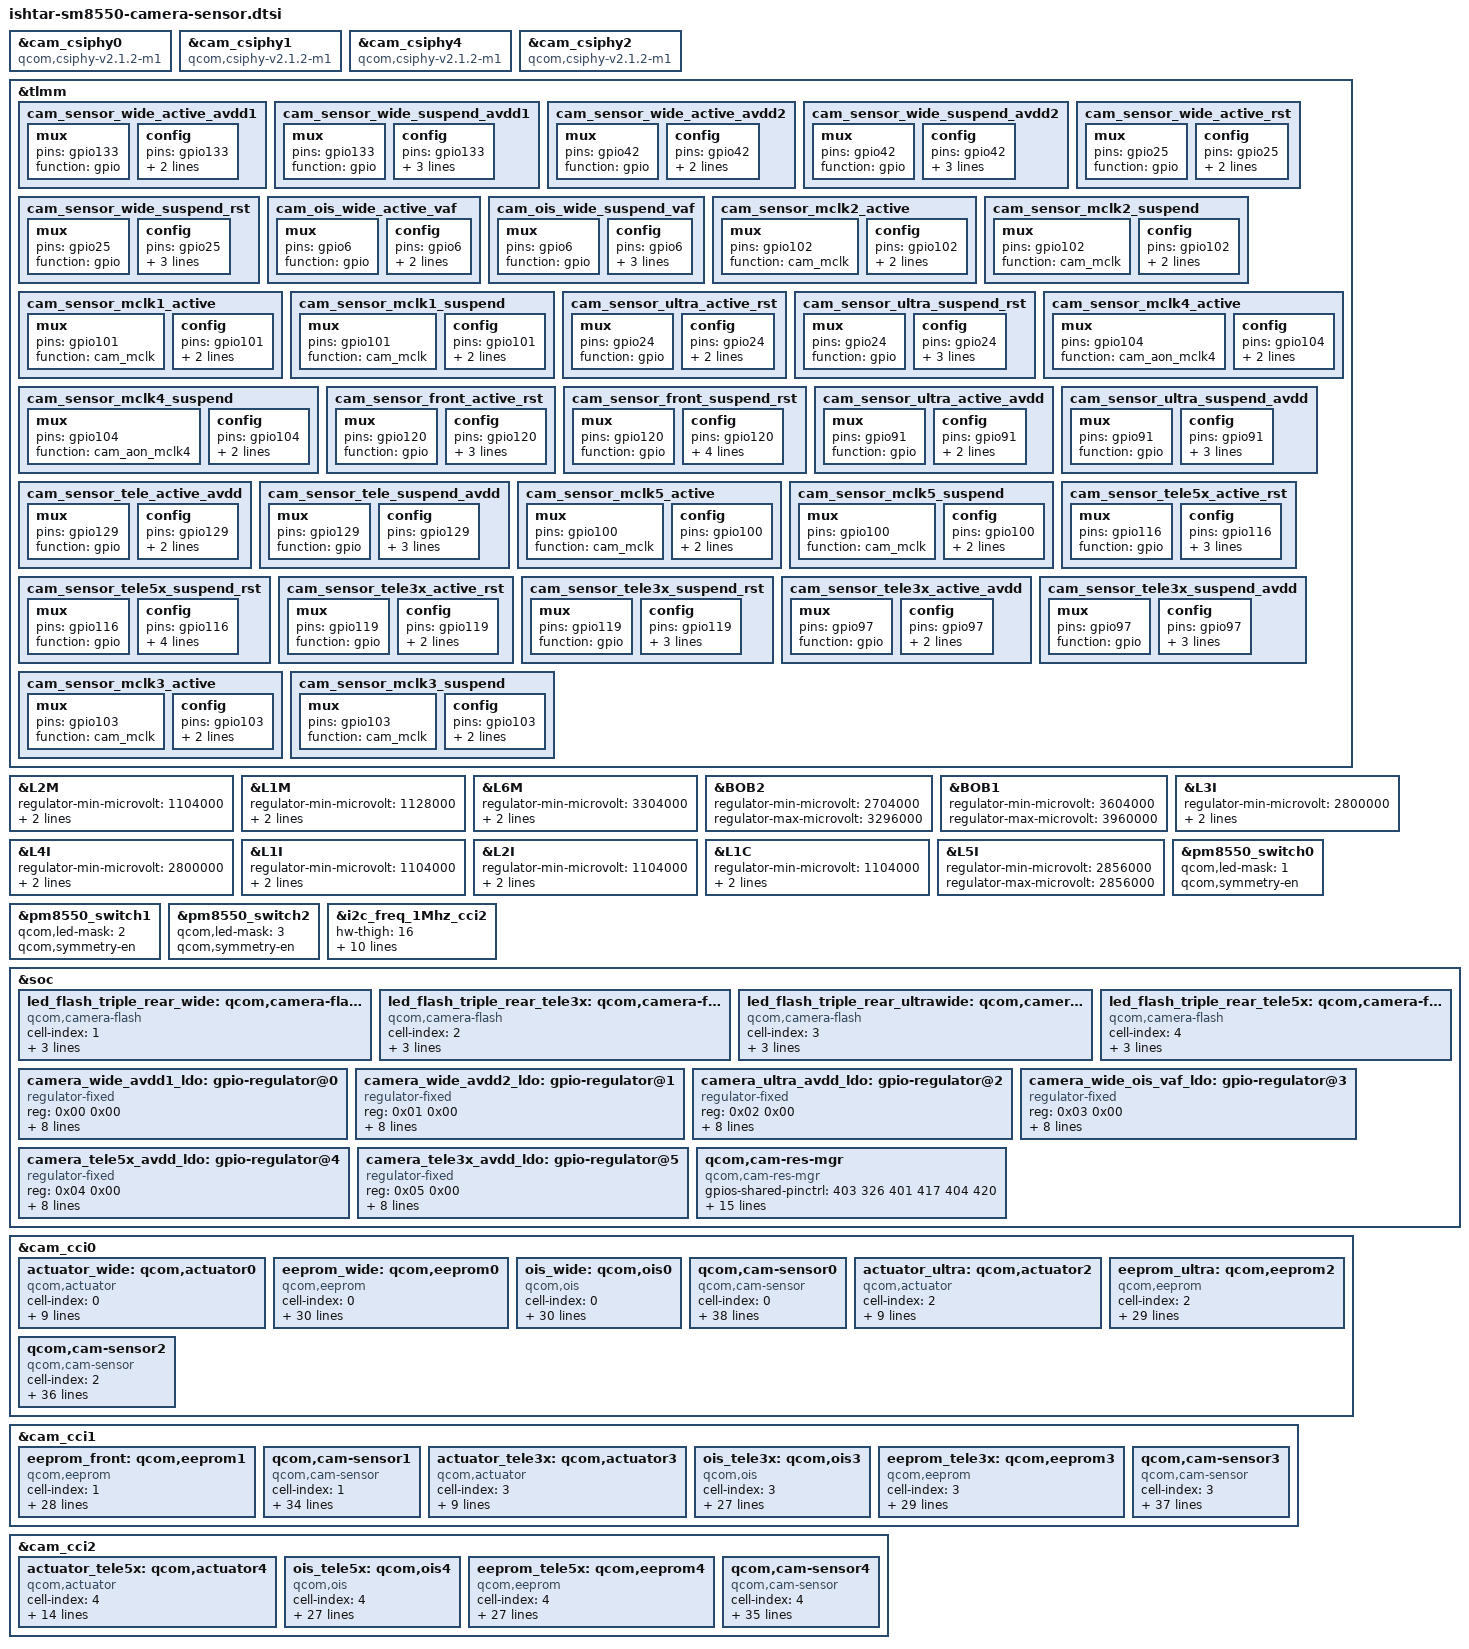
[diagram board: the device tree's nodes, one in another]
#include <dt-bindings/msm-camera.h>

//tele 5x
&cam_csiphy0 {
	compatible = "qcom,csiphy-v2.1.2-m1", "qcom,csiphy";
};
//ultra
&cam_csiphy1 {
	compatible = "qcom,csiphy-v2.1.2-m1", "qcom,csiphy";
};
//front
&cam_csiphy4 {
	compatible = "qcom,csiphy-v2.1.2-m1", "qcom,csiphy";
};
//wide
&cam_csiphy2 {
	compatible = "qcom,csiphy-v2.1.2-m1", "qcom,csiphy";
};

&tlmm {
	cam_sensor_wide_active_avdd1: cam_sensor_wide_active_avdd1 {
		mux {
			pins = "gpio133";
			function = "gpio";
		};

		config {
			pins = "gpio133";
			bias-disable; /* No PULL */
			drive-strength = <2>; /* 2 MA */
		};
	};

	cam_sensor_wide_suspend_avdd1: cam_sensor_wide_suspend_avdd1 {
		mux {
			pins = "gpio133";
			function = "gpio";
		};

		config {
			pins = "gpio133";
			bias-pull-down; /* PULL DOWN */
			drive-strength = <2>; /* 2 MA */
			output-low;
		};
	};

	cam_sensor_wide_active_avdd2: cam_sensor_wide_active_avdd2 {
		mux {
			pins = "gpio42";
			function = "gpio";
		};

		config {
			pins = "gpio42";
			bias-disable; /* No PULL */
			drive-strength = <2>; /* 2 MA */
		};
	};

	cam_sensor_wide_suspend_avdd2: cam_sensor_wide_suspend_avdd2 {
		mux {
			pins = "gpio42";
			function = "gpio";
		};

		config {
			pins = "gpio42";
			bias-pull-down; /* PULL DOWN */
			drive-strength = <2>; /* 2 MA */
			output-low;
		};
	};

	cam_sensor_wide_active_rst: cam_sensor_wide_active_rst {
		mux {
			pins = "gpio25";
			function = "gpio";
		};

		config {
			pins = "gpio25";
			bias-disable; /* No PULL */
			drive-strength = <2>; /* 2 MA */
		};
	};

	cam_sensor_wide_suspend_rst: cam_sensor_wide_suspend_rst {
		mux {
			pins = "gpio25";
			function = "gpio";
		};

		config {
			pins = "gpio25";
			bias-pull-down; /* PULL DOWN */
			drive-strength = <2>; /* 2 MA */
			output-low;
		};
	};

	cam_ois_wide_active_vaf: cam_ois_wide_active_vaf {
		mux {
			pins = "gpio6";
			function = "gpio";
		};

		config {
			pins = "gpio6";
			bias-disable; /* No PULL */
			drive-strength = <2>; /* 2 MA */
		};
	};

	cam_ois_wide_suspend_vaf: cam_ois_wide_suspend_vaf {
		mux {
			pins = "gpio6";
			function = "gpio";
		};

		config {
			pins = "gpio6";
			bias-pull-down; /* PULL DOWN */
			drive-strength = <2>; /* 2 MA */
			output-low;
		};
	};

	/* wide */
	cam_sensor_mclk2_active: cam_sensor_mclk2_active {
		/* MCLK2 */
		mux {
			pins = "gpio102";
			function = "cam_mclk";
		};

		config {
			pins = "gpio102";
			bias-disable; /* No PULL */
			drive-strength = <4>; /* 4 MA */
		};
	};

	cam_sensor_mclk2_suspend: cam_sensor_mclk2_suspend {
		/* MCLK2 */
		mux {
			pins = "gpio102";
			function = "cam_mclk";
		};

		config {
			pins = "gpio102";
			bias-pull-down; /* PULL DOWN */
			drive-strength = <4>; /* 4 MA */
		};
	};

   //ultra
	cam_sensor_mclk1_active: cam_sensor_mclk1_active {
		/* MCLK1 */
		mux {
			pins = "gpio101";
			function = "cam_mclk";
		};

		config {
			pins = "gpio101";
			bias-disable; /* No PULL */
			drive-strength = <4>; /* 4 MA */
		};
	};

	cam_sensor_mclk1_suspend: cam_sensor_mclk1_suspend {
		/* MCLK1 */
		mux {
			pins = "gpio101";
			function = "cam_mclk";
		};

		config {
			pins = "gpio101";
			bias-pull-down; /* PULL DOWN */
			drive-strength = <4>; /* 4 MA */
		};
	};

	cam_sensor_ultra_active_rst: cam_sensor_ultra_active_rst {
		mux {
			pins = "gpio24";
			function = "gpio";
		};

		config {
			pins = "gpio24";
			bias-disable; /* No PULL */
			drive-strength = <2>; /* 2 MA */
		};
	};

	cam_sensor_ultra_suspend_rst: cam_sensor_ultra_suspend_rst {
		mux {
			pins = "gpio24";
			function = "gpio";
		};

		config {
			pins = "gpio24";
			bias-pull-down; /* PULL DOWN */
			drive-strength = <2>; /* 2 MA */
			output-low;
		};
	};

    //front
	cam_sensor_mclk4_active: cam_sensor_mclk4_active {
		/* MCLK4 */
		mux {
			pins = "gpio104";
			function = "cam_aon_mclk4";
		};

		config {
			pins = "gpio104";
			bias-disable; /* No PULL */
			drive-strength = <4>; /* 4 MA */
		};
	};

	cam_sensor_mclk4_suspend: cam_sensor_mclk4_suspend {
		/* MCLK4 */
		mux {
			pins = "gpio104";
			function = "cam_aon_mclk4";
		};

		config {
			pins = "gpio104";
			bias-pull-down; /* PULL DOWN */
			drive-strength = <4>; /* 4 MA */
		};
	};

	cam_sensor_front_active_rst: cam_sensor_front_active_rst {
		mux {
			pins = "gpio120";
			function = "gpio";
		};

		config {
			pins = "gpio120";
			bias-disable; /* No PULL */
			drive-strength = <2>; /* 2 MA */
			qcom,apps;
		};
	};

	cam_sensor_front_suspend_rst: cam_sensor_front_suspend_rst {
		mux {
			pins = "gpio120";
			function = "gpio";
		};

		config {
			pins = "gpio120";
			bias-pull-down; /* PULL DOWN */
			drive-strength = <2>; /* 2 MA */
			output-low;
			qcom,remote;
		};

	};

	cam_sensor_ultra_active_avdd: cam_sensor_ultra_active_avdd {
		mux {
			pins = "gpio91";
			function = "gpio";
		};

		config {
			pins = "gpio91";
			bias-disable; /* No PULL */
			drive-strength = <2>; /* 2 MA */
		};
	};

	cam_sensor_ultra_suspend_avdd: cam_sensor_ultra_suspend_avdd {
		mux {
			pins = "gpio91";
			function = "gpio";
		};

		config {
			pins = "gpio91";
			bias-pull-down; /* PULL DOWN */
			drive-strength = <2>; /* 2 MA */
			output-low;
		};
	};

	cam_sensor_tele_active_avdd: cam_sensor_tele_active_avdd {
		mux {
			pins = "gpio129";
			function = "gpio";
		};

		config {
			pins = "gpio129";
			bias-disable; /* No PULL */
			drive-strength = <2>; /* 2 MA */
		};
	};

	cam_sensor_tele_suspend_avdd: cam_sensor_tele_suspend_avdd {
		mux {
			pins = "gpio129";
			function = "gpio";
		};

		config {
			pins = "gpio129";
			bias-pull-down; /* PULL DOWN */
			drive-strength = <2>; /* 2 MA */
			output-low;
		};
	};

    //tele
	cam_sensor_mclk5_active: cam_sensor_mclk5_active {
		/* MCLK4 */
		mux {
			pins = "gpio100";
			function = "cam_mclk";
		};

		config {
			pins = "gpio100";
			bias-disable; /* No PULL */
			drive-strength = <4>; /* 4 MA */
		};
	};

	cam_sensor_mclk5_suspend: cam_sensor_mclk5_suspend {
		/* MCLK4 */
		mux {
			pins = "gpio100";
			function = "cam_mclk";
		};

		config {
			pins = "gpio100";
			bias-pull-down; /* PULL DOWN */
			drive-strength = <4>; /* 4 MA */
		};
	};

	cam_sensor_tele5x_active_rst: cam_sensor_tele5x_active_rst {
		mux {
			pins = "gpio116";
			function = "gpio";
		};

		config {
			pins = "gpio116";
			bias-disable; /* No PULL */
			drive-strength = <2>; /* 2 MA */
			qcom,apps;
		};
	};

	cam_sensor_tele5x_suspend_rst: cam_sensor_tele5x_suspend_rst {
		mux {
			pins = "gpio116";
			function = "gpio";
		};

		config {
			pins = "gpio116";
			bias-pull-down; /* PULL DOWN */
			drive-strength = <2>; /* 2 MA */
			output-low;
			qcom,remote;
		};

	};


    /* tele3x */
	cam_sensor_tele3x_active_rst: cam_sensor_tele3x_active_rst {
		mux {
			pins = "gpio119";
			function = "gpio";
		};

		config {
			pins = "gpio119";
			bias-disable; /* No PULL */
			drive-strength = <2>; /* 2 MA */
		};
	};

	cam_sensor_tele3x_suspend_rst: cam_sensor_tele3x_suspend_rst {
		mux {
			pins = "gpio119";
			function = "gpio";
		};

		config {
			pins = "gpio119";
			bias-pull-down; /* PULL DOWN */
			drive-strength = <2>; /* 2 MA */
			output-low;
		};
	};

	cam_sensor_tele3x_active_avdd: cam_sensor_tele3x_active_avdd {
		mux {
			pins = "gpio97";
			function = "gpio";
		};

		config {
			pins = "gpio97";
			bias-disable; /* No PULL */
			drive-strength = <2>; /* 2 MA */
		};
	};

	cam_sensor_tele3x_suspend_avdd: cam_sensor_tele3x_suspend_avdd {
		mux {
			pins = "gpio97";
			function = "gpio";
		};

		config {
			pins = "gpio97";
			bias-pull-down; /* PULL DOWN */
			drive-strength = <2>; /* 2 MA */
			output-low;
		};
	};

	cam_sensor_mclk3_active: cam_sensor_mclk3_active {
		/* MCLK3 */
		mux {
			pins = "gpio103";
			function = "cam_mclk";
		};

		config {
			pins = "gpio103";
			bias-disable; /* No PULL */
			drive-strength = <4>; /* 4 MA */
		};
	};

	cam_sensor_mclk3_suspend: cam_sensor_mclk3_suspend {
		/* MCLK3 */
		mux {
			pins = "gpio103";
			function = "cam_mclk";
		};

		config {
			pins = "gpio103";
			bias-pull-down; /* PULL DOWN */
			drive-strength = <4>; /* 4 MA */
		};
	};

};

&L2M {
	regulator-min-microvolt = <1104000>;
	regulator-max-microvolt = <1104000>;
	qcom,init-voltage = <1104000>;
};

&L1M {
	regulator-min-microvolt = <1128000>;
	regulator-max-microvolt = <1128000>;
	qcom,init-voltage = <1128000>;
};

&L6M {
	regulator-min-microvolt = <3304000>;
	regulator-max-microvolt = <3304000>;
	qcom,init-voltage = <3304000>;
};

&BOB2 {
	regulator-min-microvolt = <2704000>;
	regulator-max-microvolt = <3296000>;
};

/* wide VAF parent*/
&BOB1 {
	regulator-min-microvolt = <3604000>;
	regulator-max-microvolt = <3960000>;
};

&L3I {
	regulator-min-microvolt = <2800000>;
	regulator-max-microvolt = <2800000>;
	qcom,min-dropout-voltage = <152000>;
};

&L4I {
	regulator-min-microvolt = <2800000>;
	regulator-max-microvolt = <2800000>;
	qcom,min-dropout-voltage = <152000>;
};

&L1I{
	regulator-min-microvolt = <1104000>;
	regulator-max-microvolt = <1104000>;
	qcom,init-voltage = <1104000>;
};

&L2I{
	regulator-min-microvolt = <1104000>;
	regulator-max-microvolt = <1104000>;
	qcom,init-voltage = <1104000>;
};

&L1C {
	regulator-min-microvolt = <1104000>;
	regulator-max-microvolt = <1104000>;
	qcom,init-voltage = <1104000>;
};

&L5I {
	regulator-min-microvolt = <2856000>;
	regulator-max-microvolt = <2856000>;
};

&pm8550_switch0 {
	qcom,led-mask = <1>; /* only Channels 1  0001 */
	qcom,symmetry-en;
};

&pm8550_switch1 {
	qcom,led-mask = <2>; /* only Channels 2  0010*/
	qcom,symmetry-en;
};

&pm8550_switch2 {
	qcom,led-mask = <3>; /* open 1,2 Channels  0011 for flash0 flash1 */
	qcom,symmetry-en;
};


// Enable stretch for tele5x sem1217.
&i2c_freq_1Mhz_cci2{
	hw-thigh = <16>;
	hw-tlow = <22>;
	hw-tsu-sto = <17>;
	hw-tsu-sta = <18>;
	hw-thd-dat = <16>;
	hw-thd-sta = <15>;
	hw-tbuf = <24>;
	hw-scl-stretch-en = <1>;
	hw-trdhld = <3>;
	hw-tsp = <3>;
	cci-clk-src = <37500000>;
	status = "ok";
};

&soc {
	led_flash_triple_rear_wide: qcom,camera-flash1 {
		cell-index = <1>;
		compatible = "qcom,camera-flash";
		flash-source = <&pm8550_flash0 &pm8550_flash1>;
		torch-source = <&pm8550_torch0 &pm8550_torch1>;
		switch-source = <&pm8550_switch2>;
		status = "ok";
	};

	led_flash_triple_rear_tele3x: qcom,camera-flash2 {
		cell-index = <2>;
		compatible = "qcom,camera-flash";
		flash-source = <&pm8550_flash0 &pm8550_flash1>;
		torch-source = <&pm8550_torch0 &pm8550_torch1>;
		switch-source = <&pm8550_switch2>;
		status = "ok";
	};

	led_flash_triple_rear_ultrawide: qcom,camera-flash3 {
		cell-index = <3>;
		compatible = "qcom,camera-flash";
		flash-source = <&pm8550_flash0 &pm8550_flash1>;
		torch-source = <&pm8550_torch0 &pm8550_torch1>;
		switch-source = <&pm8550_switch2>;
		status = "ok";
	};

	led_flash_triple_rear_tele5x: qcom,camera-flash4 {
		cell-index = <4>;
		compatible = "qcom,camera-flash";
		flash-source = <&pm8550_flash0 &pm8550_flash1>;
		torch-source = <&pm8550_torch0 &pm8550_torch1>;
		switch-source = <&pm8550_switch2>;
		status = "ok";
	};

	camera_wide_avdd1_ldo: gpio-regulator@0 {
		compatible = "regulator-fixed";
		reg = <0x00 0x00>;
		regulator-name = "camera_wide_avdd1_ldo";
		regulator-min-microvolt = <2800000>;
		regulator-max-microvolt = <2800000>;
		regulator-enable-ramp-delay = <100>;
		enable-active-high;
		gpio = <&tlmm 133 0>;
		pinctrl-names = "wide_avdd1_active", "wide_avdd1_suspend";
		pinctrl-0 = <&cam_sensor_wide_active_avdd1
					&cam_sensor_wide_suspend_avdd1>;
	};

	camera_wide_avdd2_ldo: gpio-regulator@1 {
		compatible = "regulator-fixed";
		reg = <0x01 0x00>;
		regulator-name = "camera_wide_avdd2_ldo";
		regulator-min-microvolt = <1800000>;
		regulator-max-microvolt = <1800000>;
		regulator-enable-ramp-delay = <100>;
		enable-active-high;
		gpio = <&tlmm 42 0>;
		pinctrl-names = "wide_avdd2_active", "wide_avdd2_suspend";
		pinctrl-0 = <&cam_sensor_wide_active_avdd2
					&cam_sensor_wide_suspend_avdd2>;
	};


	camera_ultra_avdd_ldo: gpio-regulator@2 {
		compatible = "regulator-fixed";
		reg = <0x02 0x00>;
		regulator-name = "camera_ultra_avdd_ldo";
		regulator-min-microvolt = <2800000>;
		regulator-max-microvolt = <2800000>;
		regulator-enable-ramp-delay = <100>;
		enable-active-high;
		gpio = <&tlmm 91 0>;
		pinctrl-names = "tele_avdd_active", "tele_avdd_suspend";
		pinctrl-0 = <&cam_sensor_ultra_active_avdd
					&cam_sensor_ultra_suspend_avdd>;
		//vin-supply = <&BOB2>;
	};

	camera_wide_ois_vaf_ldo: gpio-regulator@3 {
		compatible = "regulator-fixed";
		reg = <0x03 0x00>;
		regulator-name = "camera_wide_ois_vaf_ldo";
		regulator-min-microvolt = <5000000>;
		regulator-max-microvolt = <5000000>;
		regulator-enable-ramp-delay = <100>;
		enable-active-high;
		gpio = <&tlmm 6 0>;
		pinctrl-names = "wide_ois_vaf_active", "wide_ois_vaf_suspend";
		pinctrl-0 = <&cam_ois_wide_active_vaf
					&cam_ois_wide_suspend_vaf>;
        };

	camera_tele5x_avdd_ldo: gpio-regulator@4 {
		compatible = "regulator-fixed";
		reg = <0x04 0x00>;
		regulator-name = "camera_tele5x_avdd_ldo";
		regulator-min-microvolt = <2800000>;
		regulator-max-microvolt = <2800000>;
		regulator-enable-ramp-delay = <100>;
		enable-active-high;
		gpio = <&tlmm 129 0>;
		pinctrl-names = "tele_avdd_active", "tele_avdd_suspend";
		pinctrl-0 = <&cam_sensor_tele_active_avdd
					&cam_sensor_tele_suspend_avdd>;
		//vin-supply = <&BOB2>;
	};

	camera_tele3x_avdd_ldo: gpio-regulator@5 {
		compatible = "regulator-fixed";
		reg = <0x05 0x00>;
		regulator-name = "camera_tele3x_avdd_ldo";
		regulator-min-microvolt = <2800000>;
		regulator-max-microvolt = <2800000>;
		regulator-enable-ramp-delay = <100>;
		enable-active-high;
		gpio = <&tlmm 97 0>;
		pinctrl-names = "tele3x_avdd_active", "tele3x_avdd_suspend";
		pinctrl-0 = <&cam_sensor_tele3x_active_avdd
					&cam_sensor_tele3x_suspend_avdd>;
	};

	qcom,cam-res-mgr {
		compatible = "qcom,cam-res-mgr";
		gpios-shared-pinctrl = <403 326 401 417 404 420>;
		shared-pctrl-gpio-names = "cam_wide", "cam_wide", "cam_tele5x", "cam_tele5x", "cam_tele3x", "cam_tele3x";
		pinctrl-names = "cam_wide_active", "cam_wide_suspend", "cam_tele5x_active", "cam_tele5x_suspend", "cam_tele3x_active", "cam_tele3x_suspend";
		pinctrl-0 = <&cam_sensor_mclk2_active
				&cam_sensor_wide_active_rst>;
		pinctrl-1 = <&cam_sensor_mclk2_suspend
				&cam_sensor_wide_suspend_rst>;
		pinctrl-2 = <&cam_sensor_mclk5_active
				 &cam_sensor_tele5x_active_rst>;
		pinctrl-3 = <&cam_sensor_mclk5_suspend
				 &cam_sensor_tele5x_suspend_rst>;
		pinctrl-4 = <&cam_sensor_mclk3_active
			&cam_sensor_tele3x_active_rst>;
		pinctrl-5 = <&cam_sensor_mclk3_suspend
			&cam_sensor_tele3x_suspend_rst>;
		status = "ok";
	};
};


&cam_cci0 {
	actuator_wide: qcom,actuator0 {
		cell-index = <0>;
		compatible = "qcom,actuator";
		cci-master = <CCI_MASTER_1>;
		cam_vaf-supply = <&L6M>;
		cam_vio-supply = <&L5M>;
		cam_bob-supply = <&BOB1>;
		regulator-names = "cam_vaf", "cam_vio", "cam_bob";
		rgltr-cntrl-support;
		rgltr-min-voltage = <3304000 1800000 3604000>;
		rgltr-max-voltage = <3304000 1800000 3960000>;
		rgltr-load-current = <103000 20000 103000>;
	};

	eeprom_wide: qcom,eeprom0 {
		cell-index = <0>;
		compatible = "qcom,eeprom";
		cam_vio-supply = <&L5M>;
		cam_vdig-supply = <&L2M>;
		cam_clk-supply = <&cam_cc_titan_top_gdsc>;
		cam_vana-supply = <&camera_wide_avdd1_ldo>;
		cam_v_custom1-supply = <&camera_wide_avdd2_ldo>;
		cam_v_custom2-supply = <&camera_wide_ois_vaf_ldo>;
		cam_vaf-supply = <&L6M>;
		cam_bob-supply = <&BOB1>;
		cam_bob2-supply = <&BOB2>;
		regulator-names = "cam_vio", "cam_vdig",
			"cam_clk", "cam_vana", "cam_v_custom1", "cam_v_custom2", "cam_vaf", "cam_bob","cam_bob2";
		rgltr-cntrl-support;
		rgltr-min-voltage = <1800000 1104000 0 2800000 1800000 5000000 3304000 3604000 3296000>;
		rgltr-max-voltage = <1800000 1104000 0 2800000 1800000 5000000 3304000 3960000 3296000>;
		rgltr-load-current = <155000 680000 0 50000 30000 103000 103000 103000 2000000>;
		use-shared-clk;
		gpio-no-mux = <0>;
		gpios = <&tlmm 102 0>,
			<&tlmm 25 0>;
		gpio-reset = <1>;
		gpio-req-tbl-num = <0 1>;
		gpio-req-tbl-flags = <1 0>;
		gpio-req-tbl-label = "CAMIF_MCLK0",
					"CAM_RESET0";
		cci-master = <CCI_MASTER_1>;
		clocks = <&camcc CAM_CC_MCLK2_CLK>;
		clock-names = "cam_clk";
		clock-cntl-level = "nominal";
		clock-rates = <19200000>;
		status = "ok";
	};

	ois_wide: qcom,ois0 {
		cell-index = <0>;
		compatible = "qcom,ois";
		cam_vio-supply = <&L5M>;
		cam_vdig-supply = <&L2M>;
		cam_clk-supply = <&cam_cc_titan_top_gdsc>;
		cam_vana-supply = <&camera_wide_avdd1_ldo>;
		cam_v_custom1-supply = <&camera_wide_avdd2_ldo>;
		cam_v_custom2-supply = <&camera_wide_ois_vaf_ldo>;
		cam_vaf-supply = <&L6M>;
		cam_bob-supply = <&BOB1>;
		cam_bob2-supply = <&BOB2>;
		regulator-names = "cam_vio", "cam_vdig",
			"cam_clk", "cam_vana", "cam_v_custom1", "cam_v_custom2", "cam_vaf", "cam_bob","cam_bob2";
		rgltr-cntrl-support;
		rgltr-min-voltage = <1800000 1104000 0 2800000 1800000 5000000 3304000 3604000 3296000>;
		rgltr-max-voltage = <1800000 1104000 0 2800000 1800000 5000000 3304000 3960000 3296000>;
		rgltr-load-current = <155000 680000 0 50000 30000 103000 103000 103000 2000000>;
		use-shared-clk;
		gpio-no-mux = <0>;
		gpios = <&tlmm 102 0>,
			<&tlmm 25 0>;
		gpio-reset = <1>;
		gpio-req-tbl-num = <0 1>;
		gpio-req-tbl-flags = <1 0>;
		gpio-req-tbl-label = "CAMIF_MCLK0",
					"CAM_RESET0";
		cci-master = <CCI_MASTER_1>;
		clocks = <&camcc CAM_CC_MCLK2_CLK>;
		clock-names = "cam_clk";
		clock-cntl-level = "nominal";
		clock-rates = <19200000>;
		status = "ok";
	};

	//wide imx989 sensor
	qcom,cam-sensor0 {
		cell-index = <0>;
		compatible = "qcom,cam-sensor";
		csiphy-sd-index = <2>;
		actuator-src = <&actuator_wide>;
		eeprom-src = <&eeprom_wide>;
		led-flash-src = <&led_flash_triple_rear_wide>;
		ois-src  = <&ois_wide>;
		sensor-position-roll = <90>;
		sensor-position-pitch = <0>;
		sensor-position-yaw = <180>;
		cam_vio-supply = <&L5M>;
		cam_vdig-supply = <&L2M>;
		cam_clk-supply = <&cam_cc_titan_top_gdsc>;
		cam_vana-supply = <&camera_wide_avdd1_ldo>;
		cam_v_custom1-supply = <&camera_wide_avdd2_ldo>;
		cam_v_custom2-supply = <&camera_wide_ois_vaf_ldo>;
		cam_vaf-supply = <&L6M>;
		cam_bob-supply = <&BOB1>;
		cam_bob2-supply = <&BOB2>;
		regulator-names = "cam_vio", "cam_vdig",
			"cam_clk", "cam_vana", "cam_v_custom1", "cam_v_custom2", "cam_vaf", "cam_bob","cam_bob2";
		rgltr-cntrl-support;
		rgltr-min-voltage = <1800000 1104000 0 2800000 1800000 5000000 3304000 3604000 3296000>;
		rgltr-max-voltage = <1800000 1104000 0 2800000 1800000 5000000 3304000 3960000 3296000>;
		rgltr-load-current = <155000 680000 0 50000 30000 103000 103000 103000 2000000>;
		use-shared-clk;
		gpio-no-mux = <0>;
		gpios = <&tlmm 102 0>,
			<&tlmm 25 0>;
		gpio-reset = <1>;
		gpio-req-tbl-num = <0 1>;
		gpio-req-tbl-flags = <1 0>;
		gpio-req-tbl-label = "CAMIF_MCLK0",
					"CAM_RESET0";
		cci-master = <CCI_MASTER_1>;
		clocks = <&camcc CAM_CC_MCLK2_CLK>;
		clock-names = "cam_clk";
		clock-cntl-level = "nominal";
		clock-rates = <19200000>;
		status = "ok";
	};

	actuator_ultra: qcom,actuator2 {
		cell-index = <2>;
		compatible = "qcom,actuator";
		cci-master = <CCI_MASTER_0>;
		cam_vaf-supply = <&L4M>;//AF PM8010 LDO4 2.8V
		cam_vio-supply = <&L5M>;//DOVDD PM8010 LDO5 1.8V
		cam_bob2-supply = <&BOB2>;
		regulator-names = "cam_vaf", "cam_vio", "cam_bob2";
		rgltr-cntrl-support;
		rgltr-min-voltage = <2800000 1800000 3296000>;
		rgltr-max-voltage = <2800000 1800000 3296000>;
		rgltr-load-current = <103000 155000 2000000>;
	};

	eeprom_ultra: qcom,eeprom2 {
		cell-index = <2>;
		compatible = "qcom,eeprom";
		cam_vio-supply = <&L5M>;
		cam_vdig-supply = <&L1C>;
		cam_clk-supply = <&cam_cc_titan_top_gdsc>;
		cam_vana-supply = <&camera_ultra_avdd_ldo>;
		cam_vaf-supply = <&L4M>;//AF PM8010 LDO4 2.8V
		cam_bob2-supply = <&BOB2>;
		regulator-names = "cam_vio", "cam_vdig",
			"cam_clk", "cam_vana", "cam_vaf", "cam_bob2";
		rgltr-cntrl-support;
		rgltr-min-voltage = <1800000 1104000 0 2800000 2800000 3296000>;
		rgltr-max-voltage = <1800000 1104000 0 2800000 2800000 3296000>;
		rgltr-load-current = <155000 680000 0 50000 50000 2000000>;
		gpio-no-mux = <0>;
		pinctrl-names = "cam_default", "cam_suspend";
		pinctrl-0 = <&cam_sensor_mclk1_active
			&cam_sensor_ultra_active_rst>;
		pinctrl-1 = <&cam_sensor_mclk1_suspend
			&cam_sensor_ultra_suspend_rst>;
		gpios = <&tlmm 101 0>,
			<&tlmm 24 0>;
		gpio-reset = <1>;
		gpio-req-tbl-num = <0 1>;
		gpio-req-tbl-flags = <1 0>;
		gpio-req-tbl-label = "CAMIF_MCLK1",
					"CAM_RESET1";
		cci-master = <CCI_MASTER_0>;
		clocks = <&camcc CAM_CC_MCLK1_CLK>;
		clock-names = "cam_clk";
		clock-cntl-level = "nominal";
		clock-rates = <19200000>;
		status = "ok";
	};

	//Ultra imx858 sensor
	qcom,cam-sensor2 {
		cell-index = <2>;
		compatible = "qcom,cam-sensor";
		csiphy-sd-index = <1>;
		actuator-src = <&actuator_ultra>;
		eeprom-src = <&eeprom_ultra>;
		led-flash-src = <&led_flash_triple_rear_ultrawide>;
		sensor-position-roll = <90>;
		sensor-position-pitch = <0>;
		sensor-position-yaw = <180>;
		cam_vio-supply = <&L5M>;
		cam_vdig-supply = <&L1C>;
		cam_clk-supply = <&cam_cc_titan_top_gdsc>;
		cam_vana-supply = <&camera_ultra_avdd_ldo>;
		cam_bob2-supply = <&BOB2>;
		cam_vaf-supply = <&L4M>;//AF PM8010 LDO4 2.8V
		regulator-names = "cam_vio", "cam_vdig",
			"cam_clk", "cam_vana","cam_bob2", "cam_vaf";
		rgltr-cntrl-support;
		rgltr-min-voltage = <1800000 1104000 0 2800000 3296000 2800000>;
		rgltr-max-voltage = <1800000 1104000 0 2800000 3296000 2800000>;
		rgltr-load-current = <155000 680000 0 50000 2000000 103000>;
		gpio-no-mux = <0>;
		pinctrl-names = "cam_default", "cam_suspend";
		pinctrl-0 = <&cam_sensor_mclk1_active
			&cam_sensor_ultra_active_rst>;
		pinctrl-1 = <&cam_sensor_mclk1_suspend
			&cam_sensor_ultra_suspend_rst>;
		gpios = <&tlmm 101 0>,
			<&tlmm 24 0>;
		gpio-reset = <1>;
		gpio-req-tbl-num = <0 1>;
		gpio-req-tbl-flags = <1 0>;
		gpio-req-tbl-label = "CAMIF_MCLK1",
					"CAM_RESET1";
		cci-master = <CCI_MASTER_0>;
		clocks = <&camcc CAM_CC_MCLK1_CLK>;
		clock-names = "cam_clk";
		clock-cntl-level = "nominal";
		clock-rates = <19200000>;
		status = "ok";
	};

};

&cam_cci1 {

	eeprom_front: qcom,eeprom1 {
		cell-index = <1>;
		compatible = "qcom,eeprom";
		cam_vio-supply = <&L5M>;
		cam_vdig-supply = <&L1M>;
		cam_clk-supply = <&cam_cc_titan_top_gdsc>;
		cam_vana-supply = <&L3M>;
		cam_bob2-supply = <&BOB2>;
		regulator-names = "cam_vio", "cam_vdig","cam_clk", "cam_vana", "cam_bob2";
		rgltr-cntrl-support;
		// aon-user;
		rgltr-min-voltage = <1800000 1128000 0 2800000 3296000>;
		rgltr-max-voltage = <1800000 1128000 0 2800000 3296000>;
		rgltr-load-current = <20000 50000 0  103000 2000000>;
		gpio-no-mux = <0>;
		pinctrl-names = "cam_default", "cam_suspend";
		pinctrl-0 = <&cam_sensor_mclk4_active
				 &cam_sensor_front_active_rst>;
		pinctrl-1 = <&cam_sensor_mclk4_suspend
				 &cam_sensor_front_suspend_rst>;
		gpios = <&tlmm 104 0>,
			<&tlmm 120 0>;
		gpio-reset = <1>;
		gpio-req-tbl-num = <0 1 >;
		gpio-req-tbl-flags = <1 0 >;
		gpio-req-tbl-label = "CAMIF_MCLK4",
					"CAM_RESET4";
		cci-master = <CCI_MASTER_1>;
		clocks = <&camcc CAM_CC_MCLK4_CLK>;
		clock-names = "cam_clk";
		clock-cntl-level = "nominal";
		clock-rates = <19200000>;
		status = "ok";
	};

	//Front sensor
	qcom,cam-sensor1 {
		cell-index = <1>;
		compatible = "qcom,cam-sensor";
		csiphy-sd-index = <4>;
		eeprom-src = <&eeprom_front>;
		sensor-position-roll = <270>;
		sensor-position-pitch = <0>;
		sensor-position-yaw = <0>;
		cam_vio-supply = <&L5M>;
		cam_vdig-supply = <&L1M>;
		cam_clk-supply = <&cam_cc_titan_top_gdsc>;
		cam_vana-supply = <&L3M>;
		cam_bob2-supply = <&BOB2>;
		regulator-names = "cam_vio", "cam_vdig","cam_clk", "cam_vana", "cam_bob2";
		rgltr-cntrl-support;
		aon-camera-id = <AON_CAM1>;
		rgltr-min-voltage = <1800000 1128000 0 2800000 3296000>;
		rgltr-max-voltage = <1800000 1128000 0 2800000 3296000>;
		rgltr-load-current = <20000 50000 0  103000 2000000>;
		gpio-no-mux = <0>;
		pinctrl-names = "cam_default", "cam_suspend";
		pinctrl-0 = <&cam_sensor_mclk4_active
				 &cam_sensor_front_active_rst>;
		pinctrl-1 = <&cam_sensor_mclk4_suspend
				 &cam_sensor_front_suspend_rst>;
		gpios = <&tlmm 104 0>,
			<&tlmm 120 0>;
		gpio-reset = <1>;
		gpio-req-tbl-num = <0 1 >;
		gpio-req-tbl-flags = <1 0 >;
		gpio-req-tbl-label = "CAMIF_MCLK4",
					"CAM_RESET4";
		cci-master = <CCI_MASTER_1>;
		clocks = <&camcc CAM_CC_MCLK4_CLK>;
		clock-names = "cam_clk";
		clock-cntl-level = "nominal";
		clock-rates = <19200000>;
		status = "ok";
	};

	actuator_tele3x: qcom,actuator3 {
		cell-index = <3>;
		compatible = "qcom,actuator";
		cci-master = <CCI_MASTER_0>;
		cam_vaf-supply = <&L6I>;//AF PM8008 LDO6 2.8V
		cam_vio-supply = <&L5M>;//DOVDD PM8010 LDO5 1.8V
		cam_bob2-supply = <&BOB2>;
		regulator-names = "cam_vaf", "cam_vio", "cam_bob2";
		rgltr-cntrl-support;
		rgltr-min-voltage = <2800000 1800000 3296000>;
		rgltr-max-voltage = <2800000 1800000 3296000>;
		rgltr-load-current = <103000 155000 2000000>;
	};

	ois_tele3x: qcom,ois3 {
		cell-index = <3>;
		compatible = "qcom,ois";
		cam_vio-supply = <&L5M>;  //DOVDD PM8010 LDO5 1.8V
		cam_vdig-supply = <&L2I>; //DVDD PM8008 LDO2 1.1V
		cam_clk-supply = <&cam_cc_titan_top_gdsc>; // mclk gpio119
		cam_vana-supply = <&camera_tele3x_avdd_ldo>; //AVDD gpio97 2.8V
		cam_bob2-supply = <&BOB2>;
		cam_vaf-supply = <&L6I>;//AF PM8008 LDO6 2.8V
		cam_v_custom1-supply = <&L5I>; //OIS PM8008 LDO5 2.85V
		regulator-names = "cam_vio", "cam_vdig", "cam_clk", "cam_vana", "cam_bob2", "cam_vaf", "cam_v_custom1";
		rgltr-cntrl-support;
		rgltr-min-voltage = <1800000 1104000 0 2800000 3296000 2800000 2856000>;
		rgltr-max-voltage = <1800000 1104000 0 2800000 3296000 2800000 2856000>;
		rgltr-load-current = <155000 50000 0 50000 2000000 103000 103000>;
		gpio-no-mux = <0>;
		use-shared-clk;
		gpios = <&tlmm 103 0>,
			<&tlmm 119 0>;
		gpio-reset = <1>;
		gpio-req-tbl-num = <0 1>;
		gpio-req-tbl-flags = <1 0>;
		gpio-req-tbl-label = "CAMIF_MCLK3",
			"CAM_RESET3";
		cci-master = <CCI_MASTER_0>;
		clocks = <&camcc CAM_CC_MCLK3_CLK>;
		clock-names = "cam_clk";
		clock-cntl-level = "nominal";
		clock-rates = <19200000>;
		status = "ok";
	};

	eeprom_tele3x: qcom,eeprom3 {
		cell-index = <3>;
		compatible = "qcom,eeprom";
		cam_vio-supply = <&L5M>;  					 //DOVDD PM8010 LDO5 1.8V
		cam_vdig-supply = <&L2I>; 					 //DVDD PM8008  LDO2 1.1V
		cam_clk-supply = <&cam_cc_titan_top_gdsc>;   // mclk gpio119
		cam_vana-supply = <&camera_tele3x_avdd_ldo>; //AVDD gpio97 2.8V
		cam_vaf-supply = <&L6I>;					 //AF PM8008 LDO6 2.8V
		cam_v_custom1-supply = <&L5I>;				         //OIS PM8008 LDO5 2.85V
		cam_bob1-supply = <&BOB1>;
		cam_bob2-supply = <&BOB2>;
		regulator-names = "cam_vio", "cam_vdig", "cam_clk",
			"cam_vana", "cam_vaf", "cam_v_custom1", "cam_bob1", "cam_bob2";
		rgltr-cntrl-support;
		rgltr-min-voltage = <1800000 1104000 0 2800000 2800000 2856000 3604000 3296000>;
		rgltr-max-voltage = <1800000 1104000 0 2800000 2800000 2856000 3960000 3296000>;
		rgltr-load-current = <155000 50000   0 50000   103000   103000 103000  2000000>;
		gpio-no-mux = <0>;
		use-shared-clk;
		gpios = <&tlmm 103 0>,
				<&tlmm 119 0>;
		gpio-reset = <1>;
		gpio-req-tbl-num = <0 1>;
		gpio-req-tbl-flags = <1 0>;
		gpio-req-tbl-label = "CAMIF_MCLK3",
							 "CAM_RESET3";
		cci-master = <CCI_MASTER_0>;
		clocks = <&camcc CAM_CC_MCLK3_CLK>;
		clock-names = "cam_clk";
		clock-cntl-level = "nominal";
		clock-rates = <19200000>;
		status = "ok";
	};

	/* tele3x imx858 */
	qcom,cam-sensor3 {
		cell-index = <3>;
		compatible = "qcom,cam-sensor";
		csiphy-sd-index = <3>;
		actuator-src = <&actuator_tele3x>;
		eeprom-src = <&eeprom_tele3x>;
		led-flash-src = <&led_flash_triple_rear_tele3x>;
		ois-src  = <&ois_tele3x>;
		sensor-position-roll = <90>;
		sensor-position-pitch = <0>;
		sensor-position-yaw = <180>;
		cam_vio-supply = <&L5M>;  					 //DOVDD PM8010 LDO5 1.8V
		cam_vdig-supply = <&L2I>; 					 //DVDD PM8008  LDO2 1.1V
		cam_clk-supply = <&cam_cc_titan_top_gdsc>;   // mclk gpio119
		cam_vana-supply = <&camera_tele3x_avdd_ldo>; //AVDD gpio97 2.8V
		cam_vaf-supply = <&L6I>;					 //AF PM8008 LDO6 2.8V
		cam_v_custom1-supply = <&L5I>;				        //OIS PM8008 LDO5 2.85V
		cam_bob1-supply = <&BOB1>;
		cam_bob2-supply = <&BOB2>;
		regulator-names = "cam_vio", "cam_vdig", "cam_clk",
			"cam_vana", "cam_vaf", "cam_v_custom1", "cam_bob1", "cam_bob2";
		rgltr-cntrl-support;
		rgltr-min-voltage = <1800000 1104000 0 2800000 2800000 2856000 3604000 3296000>;
		rgltr-max-voltage = <1800000 1104000 0 2800000 2800000 2856000 3960000 3296000>;
		rgltr-load-current = <155000 50000   0 50000   103000   103000 103000  2000000>;
		gpio-no-mux = <0>;
		use-shared-clk;
		gpios = <&tlmm 103 0>,
			<&tlmm 119 0>;
		gpio-reset = <1>;
		gpio-req-tbl-num = <0 1>;
		gpio-req-tbl-flags = <1 0>;
		gpio-req-tbl-label = "CAMIF_MCLK3",
			"CAM_RESET3";
		cci-master = <CCI_MASTER_0>;
		clocks = <&camcc CAM_CC_MCLK3_CLK>;
		clock-names = "cam_clk";
		clock-cntl-level = "nominal";
		clock-rates = <19200000>;
		status = "ok";
	};
};

&cam_cci2 {

	actuator_tele5x: qcom,actuator4 {
		cell-index = <4>;
		compatible = "qcom,actuator";
		cci-master = <CCI_MASTER_0>;
		cam_vaf-supply = <&L3I>;
		cam_vio-supply = <&L5M>;
		cam_v_custom1-supply = <&L4I>;/*OIS AVDD*/
		cam_bob2-supply = <&BOB2>;
		regulator-names = "cam_vaf", "cam_vio","cam_v_custom1","cam_bob2";
		rgltr-cntrl-support;
		rgltr-min-voltage = <2800000 1800000 2800000 3296000>;
		rgltr-max-voltage = <2800000 1800000 2800000 3296000>;
		rgltr-load-current = <103000 155000  103000 2000000>;
	};

	ois_tele5x: qcom,ois4 {
		cell-index = <4>;
		compatible = "qcom,ois";
		cam_vio-supply = <&L5M>;
		cam_vdig-supply = <&L1I>;//pm8008 LDO1
		cam_clk-supply = <&cam_cc_titan_top_gdsc>;
		cam_vana-supply = <&camera_tele5x_avdd_ldo>;
		cam_v_custom1-supply = <&L4I>;/*OIS AVDD*/
		cam_vaf-supply =<&L3I>;
		cam_bob2-supply = <&BOB2>;
		regulator-names = "cam_vio", "cam_vdig",
				"cam_clk", "cam_vana", "cam_v_custom1", "cam_vaf","cam_bob2";
		rgltr-cntrl-support;
		rgltr-min-voltage = <1800000 1104000 0 2800000 2800000 2800000 3296000>;
		rgltr-max-voltage = <1800000 1104000 0 2800000 2800000 2800000 3296000>;
		rgltr-load-current = <155000 50000 0 50000 103000 103000 2000000>;
		gpio-no-mux = <0>;
		use-shared-clk;
		gpios = <&tlmm 100 0>,
			<&tlmm 116 0>;
		gpio-reset = <1>;
		gpio-req-tbl-num = <0 1>;
		gpio-req-tbl-flags = <1 0>;
		gpio-req-tbl-label = "CAMIF_MCLK5",
					"CAM_RESET5";
		cci-master = <CCI_MASTER_0>;
		clocks = <&camcc CAM_CC_MCLK0_CLK>;
		clock-names = "cam_clk";
		clock-cntl-level = "nominal";
		clock-rates = <19200000>;
		status = "ok";
	};

	eeprom_tele5x: qcom,eeprom4 {
		cell-index = <4>;
		compatible = "qcom,eeprom";
		cam_vio-supply = <&L5M>;
		cam_vdig-supply = <&L1I>;//pm8008 LDO1
		cam_clk-supply = <&cam_cc_titan_top_gdsc>;
		cam_vana-supply = <&camera_tele5x_avdd_ldo>;
		cam_vaf-supply = <&L3I>;
		cam_v_custom1-supply = <&L4I>;/*OIS AVDD*/
		// cam_v_custom1-supply = <&L16B>;
		cam_bob2-supply = <&BOB2>;
		regulator-names = "cam_vio", "cam_vdig",
				"cam_clk", "cam_vana","cam_vaf","cam_v_custom1","cam_bob2";
		rgltr-cntrl-support;
		rgltr-min-voltage = <1800000 1104000 0 2800000 2800000 2800000 3296000>;
		rgltr-max-voltage = <1800000 1104000 0 2800000 2800000 2800000 3296000>;
		rgltr-load-current = <155000 50000 0 50000 103000 103000 2000000>;
		gpio-no-mux = <0>;
		use-shared-clk;
		gpios = <&tlmm 100 0>,
			<&tlmm 116 0>;
		gpio-reset = <1>;
		gpio-req-tbl-num = <0 1>;
		gpio-req-tbl-flags = <1 0>;
		gpio-req-tbl-label = "CAMIF_MCLK5",
					"CAM_RESET5";
		cci-master = <CCI_MASTER_0>;
		clocks = <&camcc CAM_CC_MCLK0_CLK>;
		clock-names = "cam_clk";
		clock-cntl-level = "nominal";
		clock-rates = <19200000>;
		status = "ok";
	};

	//tele5x imx858 sensor
	qcom,cam-sensor4 {
		cell-index = <4>;
		compatible = "qcom,cam-sensor";
		csiphy-sd-index = <0>;
		actuator-src = <&actuator_tele5x>;
		eeprom-src = <&eeprom_tele5x>;
		led-flash-src = <&led_flash_triple_rear_tele5x>;
		ois-src  = <&ois_tele5x>;
		sensor-position-roll = <90>;
		sensor-position-pitch = <0>;
		sensor-position-yaw = <180>;
		cam_vio-supply = <&L5M>;
		cam_vdig-supply = <&L1I>;//pm8008 LDO1
		cam_clk-supply = <&cam_cc_titan_top_gdsc>;
		cam_vana-supply = <&camera_tele5x_avdd_ldo>;
		cam_v_custom1-supply = <&L4I>;/*OIS AVDD*/
		cam_vaf-supply = <&L3I>;
		cam_bob2-supply = <&BOB2>;
		regulator-names = "cam_vio", "cam_vdig",
				"cam_clk", "cam_vana", "cam_v_custom1", "cam_vaf","cam_bob2";
		rgltr-cntrl-support;
		rgltr-min-voltage = <1800000 1104000 0 2800000 2800000 2800000 3296000>;
		rgltr-max-voltage = <1800000 1104000 0 2800000 2800000 2800000 3296000>;
		rgltr-load-current = <155000 50000 0 50000 103000 103000 2000000>;
		gpio-no-mux = <0>;
		use-shared-clk;
		gpios = <&tlmm 100 0>,
			<&tlmm 116 0>;
		gpio-reset = <1>;
		gpio-req-tbl-num = <0 1>;
		gpio-req-tbl-flags = <1 0>;
		gpio-req-tbl-label = "CAMIF_MCLK5",
					"CAM_RESET5";
		cci-master = <CCI_MASTER_0>;
		clocks = <&camcc CAM_CC_MCLK0_CLK>;
		clock-names = "cam_clk";
		clock-cntl-level = "nominal";
		clock-rates = <19200000>;
		status = "ok";
	};

};
